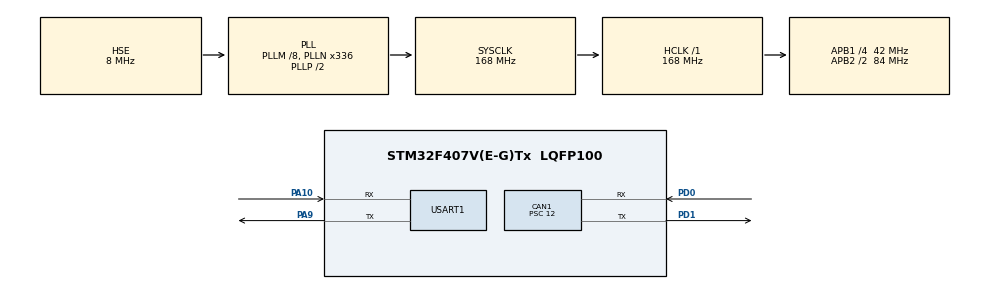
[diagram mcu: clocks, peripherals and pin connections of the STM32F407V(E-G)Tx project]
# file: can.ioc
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CAN1.AWUM=DISABLE
CAN1.BS1=CAN_BS1_6TQ
CAN1.BS2=CAN_BS2_7TQ
CAN1.CalculateBaudRate=250000
CAN1.CalculateTimeBit=4000
CAN1.CalculateTimeQuantum=285.7142857142857
CAN1.NART=ENABLE
CAN1.Prescaler=12
Mcu.Family=STM32F4
Mcu.Name=STM32F407V(E-G)Tx
Mcu.Package=LQFP100
NVIC.CAN1_RX0_IRQn=true\:0\:0\:false\:false\:true\:true\:true\:true
NVIC.PriorityGroup=NVIC_PRIORITYGROUP_4
NVIC.USART1_IRQn=true\:0\:0\:false\:false\:true\:true\:true\:true
PA10.GPIO_PuPd=GPIO_PULLUP
PA10.GPIO_Speed=GPIO_SPEED_FREQ_MEDIUM
PA10.Mode=Asynchronous
PA10.Signal=USART1_RX
PA9.GPIO_PuPd=GPIO_PULLUP
PA9.GPIO_Speed=GPIO_SPEED_FREQ_MEDIUM
PA9.Mode=Asynchronous
PA9.Signal=USART1_TX
PC14-OSC32_IN.Mode=LSE-External-Oscillator
PC14-OSC32_IN.Signal=RCC_OSC32_IN
PC15-OSC32_OUT.Mode=LSE-External-Oscillator
PC15-OSC32_OUT.Signal=RCC_OSC32_OUT
PD0.Mode=CAN_Activate
PD0.Signal=CAN1_RX
PD1.Mode=CAN_Activate
PD1.Signal=CAN1_TX
PH0-OSC_IN.Mode=HSE-External-Oscillator
PH0-OSC_IN.Signal=RCC_OSC_IN
PH1-OSC_OUT.Mode=HSE-External-Oscillator
PH1-OSC_OUT.Signal=RCC_OSC_OUT
ProjectManager.HeapSize=0x200
ProjectManager.StackSize=0x400
ProjectManager.TargetToolchain=STM32CubeIDE
RCC.48MHZClocksFreq_Value=84000000
RCC.AHBFreq_Value=168000000
RCC.APB1CLKDivider=RCC_HCLK_DIV4
RCC.APB1Freq_Value=42000000
RCC.APB1TimFreq_Value=84000000
RCC.APB2CLKDivider=RCC_HCLK_DIV2
RCC.APB2Freq_Value=84000000
RCC.APB2TimFreq_Value=168000000
RCC.CortexFreq_Value=168000000
RCC.HCLKFreq_Value=168000000
RCC.HSE_VALUE=8000000
RCC.HSI_VALUE=16000000
RCC.PLLM=8
RCC.PLLN=336
RCC.PLLSourceVirtual=RCC_PLLSOURCE_HSE
RCC.SYSCLKFreq_VALUE=168000000
RCC.SYSCLKSource=RCC_SYSCLKSOURCE_PLLCLK
RCC.VCOOutputFreq_Value=336000000
USART1.VirtualMode=VM_ASYNC
board=custom

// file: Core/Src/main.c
/* USER CODE BEGIN Header */
/**
  ******************************************************************************
  * @file           : main.c
  * @brief          : Main program body
  ******************************************************************************
  * @attention
  *
  * Copyright (c) 2023 STMicroelectronics.
  * All rights reserved.
  *
  * This software is licensed under terms that can be found in the LICENSE file
  * in the root directory of this software component.
  * If no LICENSE file comes with this software, it is provided AS-IS.
  *
  ******************************************************************************
  */
/* USER CODE END Header */
#include "main.h"
#include "usr_moto.h"
#include "odometry.h"

CAN_HandleTypeDef hcan1;

UART_HandleTypeDef huart1;

void SystemClock_Config(void);
static void MX_GPIO_Init(void);
static void MX_CAN1_Init(void);
static void MX_USART1_UART_Init(void);

int main(void)
{

  /* MCU Configuration--------------------------------------------------------*/

  /* Reset of all peripherals, Initializes the Flash interface and the Systick. */
  HAL_Init();

  /* Configure the system clock */
  SystemClock_Config();

  /* Initialize all configured peripherals */
  MX_GPIO_Init();
  MX_CAN1_Init();
  MX_USART1_UART_Init();
  /* USER CODE BEGIN 2 */
  HAL_CAN_Start(&hcan1);
   MotoCANReportSet(0x01, 500);
   MotoCANReportSet(0x02, 500);
  /* USER CODE END 2 */

  /* Infinite loop */
  while (1)
  {
      speed_transformation_send();
  }
}

void SystemClock_Config(void)
{
  RCC_OscInitTypeDef RCC_OscInitStruct = {0};
  RCC_ClkInitTypeDef RCC_ClkInitStruct = {0};

  /** Configure the main internal regulator output voltage
  */
  __HAL_RCC_PWR_CLK_ENABLE();
  __HAL_PWR_VOLTAGESCALING_CONFIG(PWR_REGULATOR_VOLTAGE_SCALE1);

  /** Initializes the RCC Oscillators according to the specified parameters
  * in the RCC_OscInitTypeDef structure.
  */
  RCC_OscInitStruct.OscillatorType = RCC_OSCILLATORTYPE_HSE;
  RCC_OscInitStruct.HSEState = RCC_HSE_ON;
  RCC_OscInitStruct.PLL.PLLState = RCC_PLL_ON;
  RCC_OscInitStruct.PLL.PLLSource = RCC_PLLSOURCE_HSE;
  RCC_OscInitStruct.PLL.PLLM = 8;
  RCC_OscInitStruct.PLL.PLLN = 336;
  RCC_OscInitStruct.PLL.PLLP = RCC_PLLP_DIV2;
  RCC_OscInitStruct.PLL.PLLQ = 4;
  if (HAL_RCC_OscConfig(&RCC_OscInitStruct) != HAL_OK)
  {
    Error_Handler();
  }

  /** Initializes the CPU, AHB and APB buses clocks
  */
  RCC_ClkInitStruct.ClockType = RCC_CLOCKTYPE_HCLK|RCC_CLOCKTYPE_SYSCLK
                              |RCC_CLOCKTYPE_PCLK1|RCC_CLOCKTYPE_PCLK2;
  RCC_ClkInitStruct.SYSCLKSource = RCC_SYSCLKSOURCE_PLLCLK;
  RCC_ClkInitStruct.AHBCLKDivider = RCC_SYSCLK_DIV1;
  RCC_ClkInitStruct.APB1CLKDivider = RCC_HCLK_DIV4;
  RCC_ClkInitStruct.APB2CLKDivider = RCC_HCLK_DIV2;

  if (HAL_RCC_ClockConfig(&RCC_ClkInitStruct, FLASH_LATENCY_5) != HAL_OK)
  {
    Error_Handler();
  }
}

static void MX_CAN1_Init(void)
{

  hcan1.Instance = CAN1;
  hcan1.Init.Prescaler = 12;
  hcan1.Init.Mode = CAN_MODE_NORMAL;
  hcan1.Init.SyncJumpWidth = CAN_SJW_1TQ;
  hcan1.Init.TimeSeg1 = CAN_BS1_6TQ;
  hcan1.Init.TimeSeg2 = CAN_BS2_7TQ;
  hcan1.Init.TimeTriggeredMode = DISABLE;
  hcan1.Init.AutoBusOff = DISABLE;
  hcan1.Init.AutoWakeUp = DISABLE;
  hcan1.Init.AutoRetransmission = ENABLE;
  hcan1.Init.ReceiveFifoLocked = DISABLE;
  hcan1.Init.TransmitFifoPriority = DISABLE;
  if (HAL_CAN_Init(&hcan1) != HAL_OK)
  {
    Error_Handler();
  }

}

static void MX_USART1_UART_Init(void)
{

  huart1.Instance = USART1;
  huart1.Init.BaudRate = 115200;
  huart1.Init.WordLength = UART_WORDLENGTH_8B;
  huart1.Init.StopBits = UART_STOPBITS_1;
  huart1.Init.Parity = UART_PARITY_NONE;
  huart1.Init.Mode = UART_MODE_TX_RX;
  huart1.Init.HwFlowCtl = UART_HWCONTROL_NONE;
  huart1.Init.OverSampling = UART_OVERSAMPLING_16;
  if (HAL_UART_Init(&huart1) != HAL_OK)
  {
    Error_Handler();
  }

}

static void MX_GPIO_Init(void)
{

  /* GPIO Ports Clock Enable */
  __HAL_RCC_GPIOC_CLK_ENABLE();
  __HAL_RCC_GPIOH_CLK_ENABLE();
  __HAL_RCC_GPIOA_CLK_ENABLE();
  __HAL_RCC_GPIOD_CLK_ENABLE();

}

void Error_Handler(void)
{
  __disable_irq();
  while (1)
  {
  }
}
